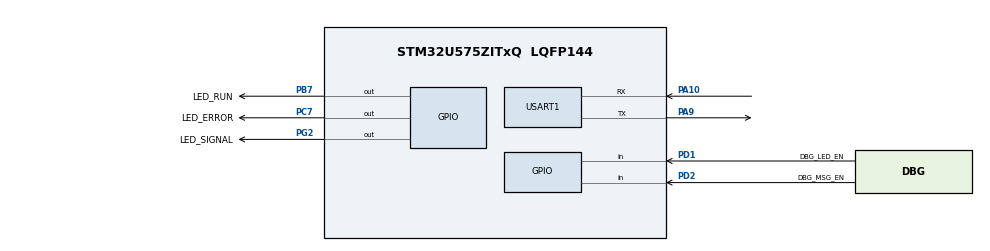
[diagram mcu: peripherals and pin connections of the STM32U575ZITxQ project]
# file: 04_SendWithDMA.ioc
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CORTEX_M33_NS.userName=CORTEX_M33
Mcu.Family=STM32U5
Mcu.Name=STM32U575ZITxQ
Mcu.Package=LQFP144
NUCLEO-U575ZI-Q.BUTTON=0
NUCLEO-U575ZI-Q.LD1=false
NUCLEO-U575ZI-Q.LD2=false
NUCLEO-U575ZI-Q.LD3=false
NUCLEO-U575ZI-Q.VCP=false
NVIC.PriorityGroup=NVIC_PRIORITYGROUP_3
NVIC.RTC_IRQn=true\:0\:0\:false\:false\:true\:true\:true\:true
NVIC.TIM17_IRQn=true\:7\:0\:false\:false\:true\:false\:true\:true
NVIC.TimeBase=TIM17_IRQn
NVIC.TimeBaseIP=TIM17
PA10.Mode=Asynchronous
PA10.Signal=USART1_RX
PA13\ (JTMS/SWDIO).Mode=Serial_Wire
PA13\ (JTMS/SWDIO).Signal=DEBUG_JTMS-SWDIO
PA14\ (JTCK/SWCLK).Mode=Serial_Wire
PA14\ (JTCK/SWCLK).Signal=DEBUG_JTCK-SWCLK
PA9.Mode=Asynchronous
PA9.Signal=USART1_TX
PB3\ (JTDO/TRACESWO).Signal=DEBUG_JTDO-SWO
PB7.GPIO_Label=LED_RUN
PB7.Signal=GPIO_Output
PC14-OSC32_IN\ (PC14).Mode=LSE-External-Oscillator
PC14-OSC32_IN\ (PC14).Signal=RCC_OSC32_IN
PC15-OSC32_OUT\ (PC15).Mode=LSE-External-Oscillator
PC15-OSC32_OUT\ (PC15).Signal=RCC_OSC32_OUT
PC7.GPIO_Label=LED_ERROR
PC7.Signal=GPIO_Output
PD1.GPIO_Label=DBG_LED_EN
PD1.GPIO_PuPd=GPIO_PULLUP
PD1.Signal=GPIO_Input
PD2.GPIO_Label=DBG_MSG_EN
PD2.GPIO_PuPd=GPIO_PULLUP
PD2.Signal=GPIO_Input
PG2.GPIO_Label=LED_SIGNAL
PG2.Signal=GPIO_Output
PWR.PowerMode=PWR_SMPS_SUPPLY
ProjectManager.HeapSize=0x200
ProjectManager.StackSize=0x400
ProjectManager.TargetToolchain=STM32CubeIDE
RCC.ADCFreq_Value=16000000
RCC.DACCLockSelectionVirtual=RCC_DAC1CLKSOURCE_LSI
RCC.EPOD_VALUE=4000000
RCC.HSE_VALUE=16000000
RCC.HSI48_VALUE=48000000
RCC.HSI_VALUE=16000000
RCC.LSIDIV_VALUE=32000
RCC.MSI_VALUE=4000000
RCC.USBFreq_Value=48000000
RCC.VCOOutputFreq_Value=516000000
RTC.WakeUpClock-WakeUp=RTC_WAKEUPCLOCK_CK_SPRE_16BITS
USART1.VirtualMode-Asynchronous=VM_ASYNC
VP_ICACHE_VS_ENABLE_ICACHE_MEMORY.Mode=Memoryregions
VP_ICACHE_VS_ICACHE.Mode=DirectMappedCache
VP_LPBAMQUEUE_VS_QUEUE.Mode=QUEUEMODE
VP_LPBAM_VS_SIG1.Mode=SmartRun
VP_LPBAM_VS_SIG4.Mode=LPDMA1
VP_MEMORYMAP_VS_MEMORYMAP.Mode=CurAppReg
VP_NUCLEO-U575ZI-Q_VS_BSP_COMMON.Mode=COMMON
VP_PWR_VS_DBSignals.Mode=DisableDeadBatterySignals
VP_PWR_VS_LPOM.Mode=PowerOptimisation
VP_PWR_VS_SECSignals.Mode=Security/Privilege
VP_RTC_VS_RTC_Activate.Mode=RTC_Enabled
VP_RTC_VS_RTC_WakeUp_intern.Mode=WakeUp
VP_SYS_VS_tim17.Mode=TIM17
board=NUCLEO-U575ZI-Q

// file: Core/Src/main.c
/* USER CODE BEGIN Header */
/**
  ******************************************************************************
  * @file           : main.c
  * @brief          : Main program body
  ******************************************************************************
  * @attention
  *
  * Copyright (c) 2026 STMicroelectronics.
  * All rights reserved.
  *
  * This software is licensed under terms that can be found in the LICENSE file
  * in the root directory of this software component.
  * If no LICENSE file comes with this software, it is provided AS-IS.
  *
  ******************************************************************************
  */
/* USER CODE END Header */
#include "main.h"
#include "icache.h"
#include "rtc.h"
#include "usart.h"

/* USER CODE BEGIN Includes */
#include "fm_main.h"
/* USER CODE END Includes */

void SystemClock_Config(void);
static void SystemPower_Config(void);

int main(void)
{

  /* MCU Configuration--------------------------------------------------------*/

  /* Reset of all peripherals, Initializes the Flash interface and the Systick. */
  HAL_Init();

  /* Configure the System Power */
  SystemPower_Config();

  /* Configure the system clock */
  SystemClock_Config();

  /* Initialize all configured peripherals */
  MX_ICACHE_Init();
  MX_RTC_Init();
  MX_USART1_UART_Init();
  /* USER CODE BEGIN 2 */

	/*
	 * MX_GPIO_Init() is intentionally not called. GPIOs used are initialized by the board layer.
	 * CubeMX is kept as a visual hardware map and to reserve the pins.
	 */

  /* USER CODE END 2 */

  /* Infinite loop */
  /* USER CODE BEGIN WHILE */
  while (1)
  {
	  FM_MAIN_Main();

    /* USER CODE END WHILE */

  }
}

void SystemClock_Config(void)
{
  RCC_OscInitTypeDef RCC_OscInitStruct = {0};
  RCC_ClkInitTypeDef RCC_ClkInitStruct = {0};

  /** Configure the main internal regulator output voltage
  */
  if (HAL_PWREx_ControlVoltageScaling(PWR_REGULATOR_VOLTAGE_SCALE4) != HAL_OK)
  {
    Error_Handler();
  }

  /** Initializes the CPU, AHB and APB buses clocks
  */
  RCC_OscInitStruct.OscillatorType = RCC_OSCILLATORTYPE_LSI|RCC_OSCILLATORTYPE_MSI;
  RCC_OscInitStruct.LSIState = RCC_LSI_ON;
  RCC_OscInitStruct.MSIState = RCC_MSI_ON;
  RCC_OscInitStruct.MSICalibrationValue = RCC_MSICALIBRATION_DEFAULT;
  RCC_OscInitStruct.MSIClockRange = RCC_MSIRANGE_4;
  RCC_OscInitStruct.LSIDiv = RCC_LSI_DIV1;
  RCC_OscInitStruct.PLL.PLLState = RCC_PLL_NONE;
  if (HAL_RCC_OscConfig(&RCC_OscInitStruct) != HAL_OK)
  {
    Error_Handler();
  }

  /** Initializes the CPU, AHB and APB buses clocks
  */
  RCC_ClkInitStruct.ClockType = RCC_CLOCKTYPE_HCLK|RCC_CLOCKTYPE_SYSCLK
                              |RCC_CLOCKTYPE_PCLK1|RCC_CLOCKTYPE_PCLK2
                              |RCC_CLOCKTYPE_PCLK3;
  RCC_ClkInitStruct.SYSCLKSource = RCC_SYSCLKSOURCE_MSI;
  RCC_ClkInitStruct.AHBCLKDivider = RCC_SYSCLK_DIV1;
  RCC_ClkInitStruct.APB1CLKDivider = RCC_HCLK_DIV1;
  RCC_ClkInitStruct.APB2CLKDivider = RCC_HCLK_DIV1;
  RCC_ClkInitStruct.APB3CLKDivider = RCC_HCLK_DIV1;

  if (HAL_RCC_ClockConfig(&RCC_ClkInitStruct, FLASH_LATENCY_0) != HAL_OK)
  {
    Error_Handler();
  }
}

/**
  * @brief Power Configuration
  * @retval None
  */
static void SystemPower_Config(void)
{
  HAL_PWREx_EnableVddIO2();

  /*
   * Disable the internal Pull-Up in Dead Battery pins of UCPD peripheral
   */
  HAL_PWREx_DisableUCPDDeadBattery();

  /*
   * Switch to SMPS regulator instead of LDO
   */
  if (HAL_PWREx_ConfigSupply(PWR_SMPS_SUPPLY) != HAL_OK)
  {
    Error_Handler();
  }
}

void HAL_TIM_PeriodElapsedCallback(TIM_HandleTypeDef *htim)
{
  if (htim->Instance == TIM17)
  {
    HAL_IncTick();
  }
}

void Error_Handler(void)
{
  __disable_irq();
  while (1)
  {
  }
}
